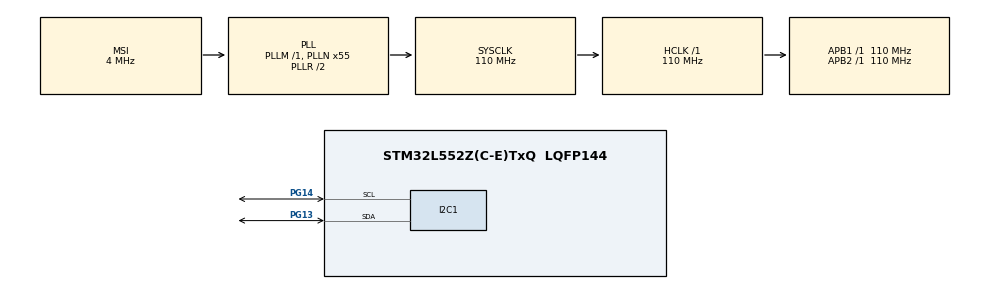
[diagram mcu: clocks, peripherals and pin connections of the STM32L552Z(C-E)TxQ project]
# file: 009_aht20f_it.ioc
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I2C1.Timing=0x60514452
Mcu.Family=STM32L5
Mcu.Name=STM32L552Z(C-E)TxQ
Mcu.Package=LQFP144
Mcu.TrustZone=disable
NUCLEO-L552ZE-Q.BUTTON=1
NUCLEO-L552ZE-Q.LD1=true
NUCLEO-L552ZE-Q.LD2=true
NUCLEO-L552ZE-Q.LD3=true
NUCLEO-L552ZE-Q.VCP=true
NVIC.EXTI13_IRQn=true\:0\:0\:false\:false\:true\:false\:true\:true
NVIC.I2C1_ER_IRQn=true\:0\:0\:false\:false\:true\:true\:true\:true
NVIC.I2C1_EV_IRQn=true\:0\:0\:false\:false\:true\:true\:true\:true
NVIC.PriorityGroup=NVIC_PRIORITYGROUP_3
PA13\ (JTMS/SWDIO).Signal=DEBUG_JTMS-SWDIO
PA14\ (JTCK/SWCLK).Signal=DEBUG_JTCK-SWCLK
PB3\ (JTDO/TRACESWO).Signal=DEBUG_JTDO-SWO
PC14-OSC32_IN\ (PC14).Signal=RCC_OSC32_IN
PC15-OSC32_OUT\ (PC15).Signal=RCC_OSC32_OUT
PG13.Mode=I2C
PG13.Signal=I2C1_SDA
PG14.Mode=I2C
PG14.Signal=I2C1_SCL
PG7.Signal=LPUART1_TX
PG8.Signal=LPUART1_RX
ProjectManager.HeapSize=0x200
ProjectManager.StackSize=0x400
ProjectManager.TargetToolchain=STM32CubeIDE
RCC.ADCCLockSelection=RCC_ADCCLKSOURCE_SYSCLK
RCC.ADCFreq_Value=110000000
RCC.AHBFreq_Value=110000000
RCC.APB1Freq_Value=110000000
RCC.APB1TimFreq_Value=110000000
RCC.APB2Freq_Value=110000000
RCC.APB2TimFreq_Value=110000000
RCC.CK48CLockSelection=RCC_USBCLKSOURCE_HSI48
RCC.CortexFreq_Value=110000000
RCC.HCLKFreq_Value=110000000
RCC.HSE_VALUE=8000000
RCC.HSI48_VALUE=48000000
RCC.HSI_VALUE=16000000
RCC.LSE_VALUE=32768
RCC.MSI_VALUE=4000000
RCC.PLLN=55
RCC.PLLSAI1N=24
RCC.RTCClockSelection=RCC_RTCCLKSOURCE_LSE
RCC.SYSCLKFreq_VALUE=110000000
RCC.SYSCLKSource=RCC_SYSCLKSOURCE_PLLCLK
RCC.USBFreq_Value=48000000
RCC.VCOOutputFreq_Value=220000000
VP_ICACHE_VS_ICACHE.Mode=DirectMappedCache
VP_NUCLEO-L552ZE-Q_VS_BSP_COMMON.Mode=COMMON
VP_PWR_VS_DBSignals.Mode=DisableDeadBatterySignals
VP_PWR_VS_SECSignals.Mode=Security/Privilege
board=NUCLEO-L552ZE-Q

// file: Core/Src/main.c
/* USER CODE BEGIN Header */
/**
  ******************************************************************************
  * @file           : main.c
  * @brief          : Main program body
  ******************************************************************************
  * @attention
  *
  * Copyright (c) 2025 STMicroelectronics.
  * All rights reserved.
  *
  * This software is licensed under terms that can be found in the LICENSE file
  * in the root directory of this software component.
  * If no LICENSE file comes with this software, it is provided AS-IS.
  *
  ******************************************************************************
  */
/* USER CODE END Header */
#include "main.h"

/* USER CODE BEGIN Includes */
#include "driver_aht20_interface.h"
/* USER CODE END Includes */

COM_InitTypeDef BspCOMInit;
I2C_HandleTypeDef hi2c1;

/* USER CODE BEGIN PV */
static aht20_handle_t gs_handle;
/* USER CODE END PV */

void SystemClock_Config(void);
static void MX_GPIO_Init(void);
static void MX_I2C1_Init(void);
static void MX_ICACHE_Init(void);

int main(void)
{

  /* USER CODE BEGIN 1 */
    uint8_t res;
    uint32_t temperature_raw;
    uint32_t humidity_raw;
    float temperature;
    uint8_t humidity;
    aht20_info_t info;
  /* USER CODE END 1 */

  /* MCU Configuration--------------------------------------------------------*/

  /* Reset of all peripherals, Initializes the Flash interface and the Systick. */
  HAL_Init();

  /* Configure the system clock */
  SystemClock_Config();

  /* Initialize all configured peripherals */
  MX_GPIO_Init();
  MX_I2C1_Init();
  MX_ICACHE_Init();

  /* Initialize leds */
  BSP_LED_Init(LED_GREEN);
  BSP_LED_Init(LED_BLUE);
  BSP_LED_Init(LED_RED);

  /* Initialize USER push-button, will be used to trigger an interrupt each time it's pressed.*/
  BSP_PB_Init(BUTTON_USER, BUTTON_MODE_EXTI);

  /* Initialize COM1 port (115200, 8 bits (7-bit data + 1 stop bit), no parity */
  BspCOMInit.BaudRate   = 115200;
  BspCOMInit.WordLength = COM_WORDLENGTH_8B;
  BspCOMInit.StopBits   = COM_STOPBITS_1;
  BspCOMInit.Parity     = COM_PARITY_NONE;
  BspCOMInit.HwFlowCtl  = COM_HWCONTROL_NONE;
  if (BSP_COM_Init(COM1, &BspCOMInit) != BSP_ERROR_NONE)
  {
    Error_Handler();
  }

  /* Infinite loop */
  /* USER CODE BEGIN WHILE */
  /* link interface function */
  DRIVER_AHT20_LINK_INIT(&gs_handle, aht20_handle_t);
  DRIVER_AHT20_LINK_IIC_INIT(&gs_handle, aht20_interface_iic_init);
  DRIVER_AHT20_LINK_IIC_DEINIT(&gs_handle, aht20_interface_iic_deinit);
  DRIVER_AHT20_LINK_IIC_READ_CMD(&gs_handle, aht20_interface_iic_read_cmd);
  DRIVER_AHT20_LINK_IIC_WRITE_CMD(&gs_handle, aht20_interface_iic_write_cmd);
  DRIVER_AHT20_LINK_DELAY_MS(&gs_handle, aht20_interface_delay_ms);
  DRIVER_AHT20_LINK_DEBUG_PRINT(&gs_handle, aht20_interface_debug_print);

  /* get aht20 information */
  res = aht20_info(&info);
  if (res != 0)
  {
      aht20_interface_debug_print("aht20: get info failed.\n");

      return 1;
  }
  else
  {
      /* print aht20 information */
      aht20_interface_debug_print("aht20: chip is %s.\n", info.chip_name);
      aht20_interface_debug_print("aht20: manufacturer is %s.\n", info.manufacturer_name);
      aht20_interface_debug_print("aht20: interface is %s.\n", info.interface);
      aht20_interface_debug_print("aht20: driver version is %d.%d.\n", info.driver_version / 1000, (info.driver_version % 1000) / 100);
      aht20_interface_debug_print("aht20: min supply voltage is %0.1fV.\n", info.supply_voltage_min_v);
      aht20_interface_debug_print("aht20: max supply voltage is %0.1fV.\n", info.supply_voltage_max_v);
      aht20_interface_debug_print("aht20: max current is %0.2fmA.\n", info.max_current_ma);
      aht20_interface_debug_print("aht20: max temperature is %0.1fC.\n", info.temperature_max);
      aht20_interface_debug_print("aht20: min temperature is %0.1fC.\n", info.temperature_min);
  }

  /* start basic read test */
  aht20_interface_debug_print("aht20: start read test.\n");

  /* aht20 init */
  res = aht20_init(&gs_handle);
  if (res != 0)
  {
      aht20_interface_debug_print("aht20: init failed.\n");

      return 1;
  }

  /* delay 2000 ms for read */
  aht20_interface_delay_ms(2000);
  while (1)
  {
      /* read temperature and humidity */
      res = aht20_read_temperature_humidity(&gs_handle, (uint32_t *)&temperature_raw, (float *)&temperature, (uint32_t *)&humidity_raw, (uint8_t *)&humidity);
      if (res != 0)
      {
          aht20_interface_debug_print("aht20: read failed.\n");
          (void)aht20_deinit(&gs_handle);

          return 1;
      }

      /* print result */
      aht20_interface_debug_print("aht20: temperature: %.01fC.\n", temperature);
      aht20_interface_debug_print("aht20: humidity: %d%%.\n", humidity);

      /* delay 2000 ms*/
      aht20_interface_delay_ms(2000);
    /* USER CODE END WHILE */

  }
}

void SystemClock_Config(void)
{
  RCC_OscInitTypeDef RCC_OscInitStruct = {0};
  RCC_ClkInitTypeDef RCC_ClkInitStruct = {0};

  /** Configure the main internal regulator output voltage
  */
  if (HAL_PWREx_ControlVoltageScaling(PWR_REGULATOR_VOLTAGE_SCALE0) != HAL_OK)
  {
    Error_Handler();
  }

  /** Initializes the RCC Oscillators according to the specified parameters
  * in the RCC_OscInitTypeDef structure.
  */
  RCC_OscInitStruct.OscillatorType = RCC_OSCILLATORTYPE_MSI;
  RCC_OscInitStruct.MSIState = RCC_MSI_ON;
  RCC_OscInitStruct.MSICalibrationValue = RCC_MSICALIBRATION_DEFAULT;
  RCC_OscInitStruct.MSIClockRange = RCC_MSIRANGE_6;
  RCC_OscInitStruct.PLL.PLLState = RCC_PLL_ON;
  RCC_OscInitStruct.PLL.PLLSource = RCC_PLLSOURCE_MSI;
  RCC_OscInitStruct.PLL.PLLM = 1;
  RCC_OscInitStruct.PLL.PLLN = 55;
  RCC_OscInitStruct.PLL.PLLP = RCC_PLLP_DIV7;
  RCC_OscInitStruct.PLL.PLLQ = RCC_PLLQ_DIV2;
  RCC_OscInitStruct.PLL.PLLR = RCC_PLLR_DIV2;
  if (HAL_RCC_OscConfig(&RCC_OscInitStruct) != HAL_OK)
  {
    Error_Handler();
  }

  /** Initializes the CPU, AHB and APB buses clocks
  */
  RCC_ClkInitStruct.ClockType = RCC_CLOCKTYPE_HCLK|RCC_CLOCKTYPE_SYSCLK
                              |RCC_CLOCKTYPE_PCLK1|RCC_CLOCKTYPE_PCLK2;
  RCC_ClkInitStruct.SYSCLKSource = RCC_SYSCLKSOURCE_PLLCLK;
  RCC_ClkInitStruct.AHBCLKDivider = RCC_SYSCLK_DIV1;
  RCC_ClkInitStruct.APB1CLKDivider = RCC_HCLK_DIV1;
  RCC_ClkInitStruct.APB2CLKDivider = RCC_HCLK_DIV1;

  if (HAL_RCC_ClockConfig(&RCC_ClkInitStruct, FLASH_LATENCY_5) != HAL_OK)
  {
    Error_Handler();
  }
}

static void MX_I2C1_Init(void)
{

  hi2c1.Instance = I2C1;
  hi2c1.Init.Timing = 0x60514452;
  hi2c1.Init.OwnAddress1 = 0;
  hi2c1.Init.AddressingMode = I2C_ADDRESSINGMODE_7BIT;
  hi2c1.Init.DualAddressMode = I2C_DUALADDRESS_DISABLE;
  hi2c1.Init.OwnAddress2 = 0;
  hi2c1.Init.OwnAddress2Masks = I2C_OA2_NOMASK;
  hi2c1.Init.GeneralCallMode = I2C_GENERALCALL_DISABLE;
  hi2c1.Init.NoStretchMode = I2C_NOSTRETCH_DISABLE;
  if (HAL_I2C_Init(&hi2c1) != HAL_OK)
  {
    Error_Handler();
  }

  /** Configure Analogue filter
  */
  if (HAL_I2CEx_ConfigAnalogFilter(&hi2c1, I2C_ANALOGFILTER_ENABLE) != HAL_OK)
  {
    Error_Handler();
  }

  /** Configure Digital filter
  */
  if (HAL_I2CEx_ConfigDigitalFilter(&hi2c1, 0) != HAL_OK)
  {
    Error_Handler();
  }

}

static void MX_ICACHE_Init(void)
{

  /** Enable instruction cache in 1-way (direct mapped cache)
  */
  if (HAL_ICACHE_ConfigAssociativityMode(ICACHE_1WAY) != HAL_OK)
  {
    Error_Handler();
  }
  if (HAL_ICACHE_Enable() != HAL_OK)
  {
    Error_Handler();
  }

}

static void MX_GPIO_Init(void)
{

  /* GPIO Ports Clock Enable */
  __HAL_RCC_GPIOC_CLK_ENABLE();
  __HAL_RCC_GPIOA_CLK_ENABLE();
  __HAL_RCC_GPIOG_CLK_ENABLE();
  HAL_PWREx_EnableVddIO2();
  __HAL_RCC_GPIOB_CLK_ENABLE();

}

void Error_Handler(void)
{
  __disable_irq();
  while (1)
  {
  }
}
